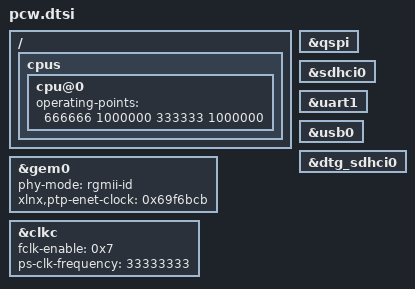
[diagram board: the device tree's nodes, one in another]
/*
 * CAUTION: This file is automatically generated by Xilinx.
 * Version:  
 * Today is: Wed Apr 24 20:59:36 2019
*/


/ {
	cpus {
		cpu@0 {
			operating-points = <666666 1000000 333333 1000000>;
		};
	};
};
&gem0 {
	phy-mode = "rgmii-id";
	status = "okay";
	xlnx,ptp-enet-clock = <0x69f6bcb>;
};
&qspi {
	status = "okay";
};
&sdhci0 {
	status = "okay";
};
&uart1 {
	status = "okay";
};
&usb0 {
	status = "okay";
};
&clkc {
	fclk-enable = <0x7>;
	ps-clk-frequency = <33333333>;
};
&dtg_sdhci0 {
	status = "okay";
};
